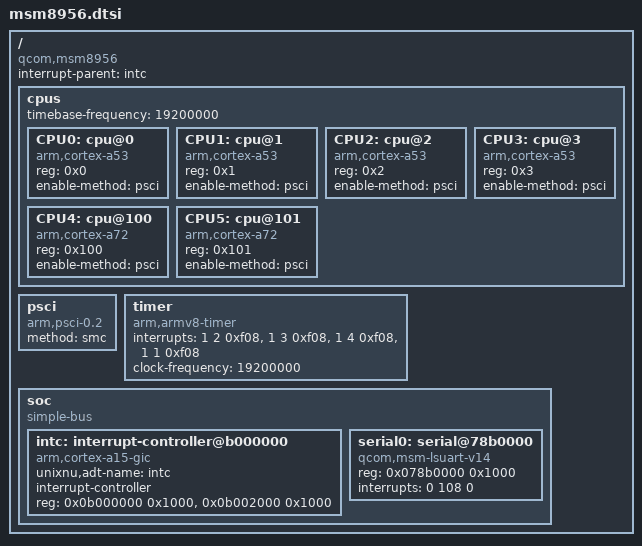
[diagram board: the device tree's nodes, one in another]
// MSM8956 (Snapdragon 650) common DTS include for UniXNU

/ {
    compatible = "qcom,msm8956";
    #address-cells = <2>;
    #size-cells = <2>;
    interrupt-parent = <&intc>;

    cpus {
        #address-cells = <1>;
        #size-cells = <0>;
        timebase-frequency = <19200000>;

        // Cortex-A53 Little Cluster (CPUs 0-3)
        CPU0: cpu@0 {
            device_type = "cpu";
            compatible = "arm,cortex-a53", "arm,armv8";
            reg = <0x0>;
            enable-method = "psci";
        };
        CPU1: cpu@1 {
            device_type = "cpu";
            compatible = "arm,cortex-a53", "arm,armv8";
            reg = <0x1>;
            enable-method = "psci";
        };
        CPU2: cpu@2 {
            device_type = "cpu";
            compatible = "arm,cortex-a53", "arm,armv8";
            reg = <0x2>;
            enable-method = "psci";
        };
        CPU3: cpu@3 {
            device_type = "cpu";
            compatible = "arm,cortex-a53", "arm,armv8";
            reg = <0x3>;
            enable-method = "psci";
        };

        // Cortex-A72 Big Cluster (CPUs 4-5)
        CPU4: cpu@100 {
            device_type = "cpu";
            compatible = "arm,cortex-a72", "arm,armv8";
            reg = <0x100>;
            enable-method = "psci";
        };
        CPU5: cpu@101 {
            device_type = "cpu";
            compatible = "arm,cortex-a72", "arm,armv8";
            reg = <0x101>;
            enable-method = "psci";
        };
    };

    psci {
        compatible = "arm,psci-0.2", "arm,psci";
        method = "smc";
    };

    timer {
        compatible = "arm,armv8-timer";
        interrupts = <1 2 0xf08>,
                     <1 3 0xf08>,
                     <1 4 0xf08>,
                     <1 1 0xf08>;
        clock-frequency = <19200000>;
    };

    soc {
        #address-cells = <1>;
        #size-cells = <1>;
        ranges = <0 0 0 0xffffffff>;
        compatible = "simple-bus";

        intc: interrupt-controller@b000000 {
            unixnu,adt-name = "intc";
            compatible = "arm,cortex-a15-gic", "qcom,msm-qgic2";
            #interrupt-cells = <3>;
            interrupt-controller;
            reg = <0x0b000000 0x1000>,
                  <0x0b002000 0x1000>;
        };

        serial0: serial@78b0000 {
            compatible = "qcom,msm-lsuart-v14", "qcom,msm-uart";
            reg = <0x078b0000 0x1000>;
            interrupts = <0 108 0>;
            status = "okay";
        };
    };
};
